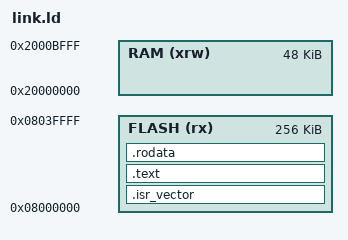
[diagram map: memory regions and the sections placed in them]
MEMORY
{
  FLASH (rx)  : ORIGIN = 0x08000000, LENGTH = 256K
  RAM   (xrw) : ORIGIN = 0x20000000, LENGTH = 48K
}
SECTIONS
{
  .isr_vector : { KEEP(*(.isr_vector)) } > FLASH
  .text : { *(.text*) } > FLASH
  .rodata : { *(.rodata*) } > FLASH
}
